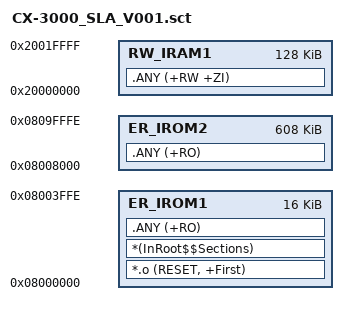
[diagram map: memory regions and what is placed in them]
; *************************************************************
; *** Scatter-Loading Description File generated by uVision ***
; *************************************************************

LR_IROM1 0x08000000 0x00003FFF  {    ; load region size_region
  ER_IROM1 0x08000000 0x00003FFF  {  ; load address = execution address
   *.o (RESET, +First)
   *(InRoot$$Sections)
   .ANY (+RO)
  }
  RW_IRAM1 0x20000000 0x00020000  {  ; RW data
   .ANY (+RW +ZI)
  }
}

LR_IROM2 0x08008000 0x00097FFF  {
  ER_IROM2 0x08008000 0x00097FFF  {  ; load address = execution address
   .ANY (+RO)
  }
}
